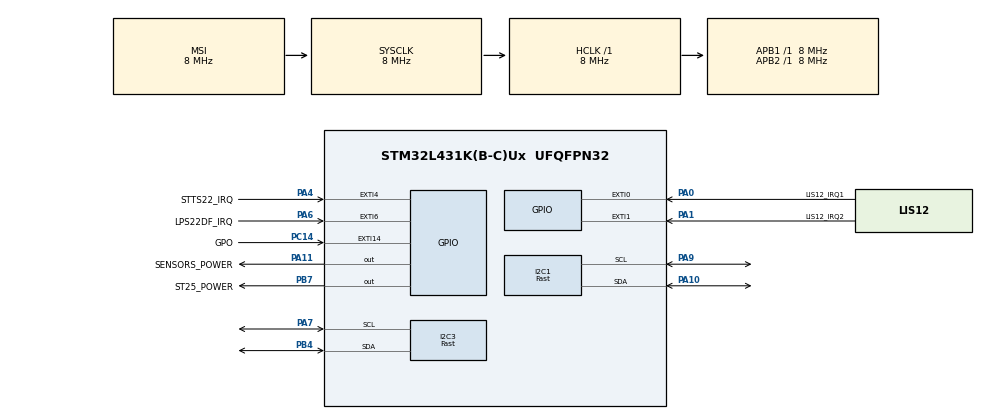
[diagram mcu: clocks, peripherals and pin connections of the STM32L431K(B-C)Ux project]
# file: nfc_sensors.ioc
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I2C1.I2C_Coeff_DF=0
I2C1.I2C_Speed_Mode=I2C_Fast
I2C1.Timing=0x0000020B
I2C3.Analog_Filter=I2C_ANALOGFILTER_ENABLE
I2C3.I2C_Coeff_DF=2
I2C3.I2C_Speed_Mode=I2C_Fast
I2C3.Speed=400
I2C3.Timing=0x00000009
Mcu.Family=STM32L4
Mcu.Name=STM32L431K(B-C)Ux
Mcu.Package=UFQFPN32
NVIC.EXTI0_IRQn=true\:0\:0\:false\:false\:true\:true\:true\:true
NVIC.PriorityGroup=NVIC_PRIORITYGROUP_4
PA0.GPIO_Label=LIS12_IRQ1
PA0.Signal=GPXTI0
PA1.GPIO_Label=LIS12_IRQ2
PA1.Signal=GPXTI1
PA10.GPIO_Pu=GPIO_NOPULL
PA10.GPIO_Speed=GPIO_SPEED_FREQ_VERY_HIGH
PA10.Mode=I2C
PA10.Signal=I2C1_SDA
PA11.GPIO_Label=SENSORS_POWER
PA11.PinState=GPIO_PIN_RESET
PA11.Signal=GPIO_Output
PA13\ (JTMS-SWDIO).Mode=Serial_Wire
PA13\ (JTMS-SWDIO).Signal=SYS_JTMS-SWDIO
PA14\ (JTCK-SWCLK).Mode=Serial_Wire
PA14\ (JTCK-SWCLK).Signal=SYS_JTCK-SWCLK
PA4.GPIO_Label=STTS22_IRQ
PA4.Signal=GPXTI4
PA6.GPIO_Label=LPS22DF_IRQ
PA6.Signal=GPXTI6
PA7.GPIO_Pu=GPIO_NOPULL
PA7.GPIO_Speed=GPIO_SPEED_FREQ_VERY_HIGH
PA7.Mode=I2C
PA7.Signal=I2C3_SCL
PA9.GPIO_Pu=GPIO_NOPULL
PA9.GPIO_Speed=GPIO_SPEED_FREQ_VERY_HIGH
PA9.Mode=I2C
PA9.Signal=I2C1_SCL
PB4\ (NJTRST).GPIO_Pu=GPIO_NOPULL
PB4\ (NJTRST).GPIO_Speed=GPIO_SPEED_FREQ_VERY_HIGH
PB4\ (NJTRST).Mode=I2C
PB4\ (NJTRST).Signal=I2C3_SDA
PB7.GPIO_Label=ST25_POWER
PB7.PinState=GPIO_PIN_RESET
PB7.Signal=GPIO_Output
PC14-OSC32_IN\ (PC14).GPIO_Label=GPO
PC14-OSC32_IN\ (PC14).GPIO_PuPd=GPIO_PULLUP
PC14-OSC32_IN\ (PC14).Signal=GPXTI14
ProjectManager.HeapSize=0x200
ProjectManager.StackSize=0x400
ProjectManager.TargetToolchain=STM32CubeIDE
RCC.ADCFreq_Value=8000000
RCC.AHBFreq_Value=8000000
RCC.APB1Freq_Value=8000000
RCC.APB1TimFreq_Value=8000000
RCC.APB2Freq_Value=8000000
RCC.APB2TimFreq_Value=8000000
RCC.CortexFreq_Value=8000000
RCC.HCLKFreq_Value=8000000
RCC.HSE_VALUE=8000000
RCC.HSI48_VALUE=48000000
RCC.HSI_VALUE=16000000
RCC.INSTRUCTION_CACHE_ENABLE=1
RCC.LSE_VALUE=32768
RCC.MSIClockRange=RCC_MSIRANGE_7
RCC.MSI_VALUE=8000000
RCC.PLLM=4
RCC.PLLR=RCC_PLLR_DIV8
RCC.PREFETCH_ENABLE=1
RCC.PWR_Regulator_Voltage_Scale=PWR_REGULATOR_VOLTAGE_SCALE2
RCC.SYSCLKFreq_VALUE=8000000
RCC.VCOOutputFreq_Value=16000000
RCC.VDD_VALUE=1.8
board=custom

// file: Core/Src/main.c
/* USER CODE BEGIN Header */
/**
  ******************************************************************************
  * @file           : main.c
  * @brief          : Main program body
  ******************************************************************************
  * @attention
  *
  * Copyright (c) 2023 STMicroelectronics.
  * All rights reserved.
  *
  * This software is licensed under terms that can be found in the LICENSE file
  * in the root directory of this software component.
  * If no LICENSE file comes with this software, it is provided AS-IS.
  *
  ******************************************************************************
  */
/* USER CODE END Header */
#include "main.h"

I2C_HandleTypeDef hi2c1;
I2C_HandleTypeDef hi2c3;

void SystemClock_Config(void);
static void MX_GPIO_Init(void);
static void MX_I2C1_Init(void);
static void MX_I2C3_Init(void);
/* USER CODE BEGIN PFP */
extern	void nfc_sensors_init(void);
extern	void nfc_sensors_loop(void);

/* USER CODE END PFP */

int main(void)
{

  /* MCU Configuration--------------------------------------------------------*/

  /* Reset of all peripherals, Initializes the Flash interface and the Systick. */
  HAL_Init();

  /* Configure the system clock */
  SystemClock_Config();

  /* Initialize all configured peripherals */
  MX_GPIO_Init();
  MX_I2C1_Init();
  MX_I2C3_Init();
  /* USER CODE BEGIN 2 */
  nfc_sensors_init();
  /* USER CODE END 2 */

  /* Infinite loop */
  /* USER CODE BEGIN WHILE */
  while (1)
  {
	  nfc_sensors_loop();
    /* USER CODE END WHILE */

  }
}

void SystemClock_Config(void)
{
  RCC_OscInitTypeDef RCC_OscInitStruct = {0};
  RCC_ClkInitTypeDef RCC_ClkInitStruct = {0};

  /** Configure the main internal regulator output voltage
  */
  if (HAL_PWREx_ControlVoltageScaling(PWR_REGULATOR_VOLTAGE_SCALE2) != HAL_OK)
  {
    Error_Handler();
  }

  /** Initializes the RCC Oscillators according to the specified parameters
  * in the RCC_OscInitTypeDef structure.
  */
  RCC_OscInitStruct.OscillatorType = RCC_OSCILLATORTYPE_MSI;
  RCC_OscInitStruct.MSIState = RCC_MSI_ON;
  RCC_OscInitStruct.MSICalibrationValue = 0;
  RCC_OscInitStruct.MSIClockRange = RCC_MSIRANGE_7;
  RCC_OscInitStruct.PLL.PLLState = RCC_PLL_NONE;
  if (HAL_RCC_OscConfig(&RCC_OscInitStruct) != HAL_OK)
  {
    Error_Handler();
  }

  /** Initializes the CPU, AHB and APB buses clocks
  */
  RCC_ClkInitStruct.ClockType = RCC_CLOCKTYPE_HCLK|RCC_CLOCKTYPE_SYSCLK
                              |RCC_CLOCKTYPE_PCLK1|RCC_CLOCKTYPE_PCLK2;
  RCC_ClkInitStruct.SYSCLKSource = RCC_SYSCLKSOURCE_MSI;
  RCC_ClkInitStruct.AHBCLKDivider = RCC_SYSCLK_DIV1;
  RCC_ClkInitStruct.APB1CLKDivider = RCC_HCLK_DIV1;
  RCC_ClkInitStruct.APB2CLKDivider = RCC_HCLK_DIV1;

  if (HAL_RCC_ClockConfig(&RCC_ClkInitStruct, FLASH_LATENCY_1) != HAL_OK)
  {
    Error_Handler();
  }
}

static void MX_I2C1_Init(void)
{

  hi2c1.Instance = I2C1;
  hi2c1.Init.Timing = 0x0000020B;
  hi2c1.Init.OwnAddress1 = 0;
  hi2c1.Init.AddressingMode = I2C_ADDRESSINGMODE_7BIT;
  hi2c1.Init.DualAddressMode = I2C_DUALADDRESS_DISABLE;
  hi2c1.Init.OwnAddress2 = 0;
  hi2c1.Init.OwnAddress2Masks = I2C_OA2_NOMASK;
  hi2c1.Init.GeneralCallMode = I2C_GENERALCALL_DISABLE;
  hi2c1.Init.NoStretchMode = I2C_NOSTRETCH_DISABLE;
  if (HAL_I2C_Init(&hi2c1) != HAL_OK)
  {
    Error_Handler();
  }

  /** Configure Analogue filter
  */
  if (HAL_I2CEx_ConfigAnalogFilter(&hi2c1, I2C_ANALOGFILTER_ENABLE) != HAL_OK)
  {
    Error_Handler();
  }

  /** Configure Digital filter
  */
  if (HAL_I2CEx_ConfigDigitalFilter(&hi2c1, 0) != HAL_OK)
  {
    Error_Handler();
  }

}

static void MX_I2C3_Init(void)
{

  hi2c3.Instance = I2C3;
  hi2c3.Init.Timing = 0x00000009;
  hi2c3.Init.OwnAddress1 = 0;
  hi2c3.Init.AddressingMode = I2C_ADDRESSINGMODE_7BIT;
  hi2c3.Init.DualAddressMode = I2C_DUALADDRESS_DISABLE;
  hi2c3.Init.OwnAddress2 = 0;
  hi2c3.Init.OwnAddress2Masks = I2C_OA2_NOMASK;
  hi2c3.Init.GeneralCallMode = I2C_GENERALCALL_DISABLE;
  hi2c3.Init.NoStretchMode = I2C_NOSTRETCH_DISABLE;
  if (HAL_I2C_Init(&hi2c3) != HAL_OK)
  {
    Error_Handler();
  }

  /** Configure Analogue filter
  */
  if (HAL_I2CEx_ConfigAnalogFilter(&hi2c3, I2C_ANALOGFILTER_ENABLE) != HAL_OK)
  {
    Error_Handler();
  }

  /** Configure Digital filter
  */
  if (HAL_I2CEx_ConfigDigitalFilter(&hi2c3, 2) != HAL_OK)
  {
    Error_Handler();
  }

}

static void MX_GPIO_Init(void)
{
  GPIO_InitTypeDef GPIO_InitStruct = {0};

  /* GPIO Ports Clock Enable */
  __HAL_RCC_GPIOC_CLK_ENABLE();
  __HAL_RCC_GPIOA_CLK_ENABLE();
  __HAL_RCC_GPIOB_CLK_ENABLE();

  /*Configure GPIO pin Output Level */
  HAL_GPIO_WritePin(SENSORS_POWER_GPIO_Port, SENSORS_POWER_Pin, GPIO_PIN_RESET);

  /*Configure GPIO pin Output Level */
  HAL_GPIO_WritePin(ST25_POWER_GPIO_Port, ST25_POWER_Pin, GPIO_PIN_RESET);

  /*Configure GPIO pin : GPO_Pin */
  GPIO_InitStruct.Pin = GPO_Pin;
  GPIO_InitStruct.Mode = GPIO_MODE_IT_RISING;
  GPIO_InitStruct.Pull = GPIO_PULLUP;
  HAL_GPIO_Init(GPO_GPIO_Port, &GPIO_InitStruct);

  /*Configure GPIO pins : LIS12_IRQ1_Pin LIS12_IRQ2_Pin STTS22_IRQ_Pin LPS22DF_IRQ_Pin */
  GPIO_InitStruct.Pin = LIS12_IRQ1_Pin|LIS12_IRQ2_Pin|STTS22_IRQ_Pin|LPS22DF_IRQ_Pin;
  GPIO_InitStruct.Mode = GPIO_MODE_IT_RISING;
  GPIO_InitStruct.Pull = GPIO_NOPULL;
  HAL_GPIO_Init(GPIOA, &GPIO_InitStruct);

  /*Configure GPIO pin : SENSORS_POWER_Pin */
  GPIO_InitStruct.Pin = SENSORS_POWER_Pin;
  GPIO_InitStruct.Mode = GPIO_MODE_OUTPUT_PP;
  GPIO_InitStruct.Pull = GPIO_NOPULL;
  GPIO_InitStruct.Speed = GPIO_SPEED_FREQ_LOW;
  HAL_GPIO_Init(SENSORS_POWER_GPIO_Port, &GPIO_InitStruct);

  /*Configure GPIO pin : ST25_POWER_Pin */
  GPIO_InitStruct.Pin = ST25_POWER_Pin;
  GPIO_InitStruct.Mode = GPIO_MODE_OUTPUT_PP;
  GPIO_InitStruct.Pull = GPIO_NOPULL;
  GPIO_InitStruct.Speed = GPIO_SPEED_FREQ_LOW;
  HAL_GPIO_Init(ST25_POWER_GPIO_Port, &GPIO_InitStruct);

  /* EXTI interrupt init*/
  HAL_NVIC_SetPriority(EXTI0_IRQn, 0, 0);
  HAL_NVIC_EnableIRQ(EXTI0_IRQn);

}

void Error_Handler(void)
{
  __disable_irq();
  while (1)
  {
  }
}
